VERSION ""

NS_ :

BS_:
BU_: TER_PEDAL ECU_CMDS
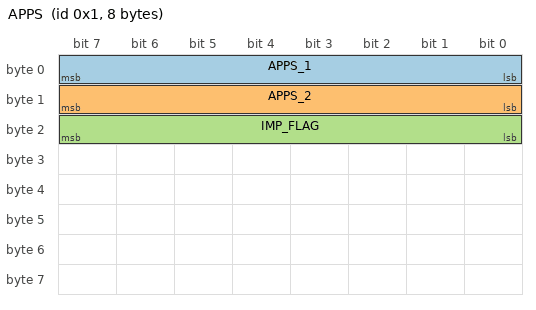
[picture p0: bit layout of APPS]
BO_ 1 APPS: 8 TER_PEDAL
   SG_ APPS_1 : 7|8@0+ (1,0) [0|255] "" Vector__XXX
   SG_ APPS_2 : 15|8@0+ (1,0) [0|255] "" Vector__XXX
   SG_ IMP_FLAG : 23|8@0+ (1,0) [0|255] "" Vector__XXX

BO_ 4 PEDAL_CMD: 8 ECU_CMDS
   SG_ CMD : 7|8@0+ (1,0) [0|1] "" Vector__XXX
   SG_ ARGS : 15|56@0+ (1,0) [0|1] "" Vector__XXX

BO_ 2 BPPS: 1 TER_PEDAL
   SG_ BPPS : 7|8@0+ (1,0) [0|1] "" Vector__XXX

BO_ 5 STEER: 8 TER_PEDAL
   SG_ WHEEL_ANGLE : 39|32@2- (1,0) [0|1] "" Vector__XXX
   SG_ STEERING_ANGLE : 7|32@2- (1,0) [0|1] "" Vector__XXX

BA_DEF_ BO_ "GenMsgBackgroundColor" STRING ;
BA_DEF_ BO_ "GenMsgForegroundColor" STRING ;
BA_DEF_ BO_ "filterlabeling" INT 0 0;
BA_DEF_ BO_ "filterlabeling" INT 0 0;
BA_DEF_DEF_ "GenMsgBackgroundColor" "#ffffff";
BA_DEF_DEF_ "GenMsgForegroundColor" "#000000";
BA_DEF_DEF_ "filterlabeling" 1;
CM_ BU_ TER_PEDAL "APPS,BPPS, Implausabilities...";
CM_ BU_ ECU_CMDS "Contains messages to control ECUs";
CM_ BO_ 1 "Accelerator Pedal Position Sensor and Implausability";
CM_ BO_ 4 "Format:[1byte](Command)[7byte](Arguments)";
CM_ BO_ 2 "Brake Pedal position Sensor";
CM_ BO_ 5 "Steering Wheel + Steer angle";
CM_ SG_ 5 WHEEL_ANGLE "Angle_of_the_wheel_with_the_heading_axis";
CM_ SG_ 5 STEERING_ANGLE "Angle_of_the_steering_Wheel";
VAL_ 1 APPS_1 0 "No Description";
